# STM32H563 register map
STM32H563xx Cortex-M33 mini SVD fixture for testing
CPU: CM33
Registers are 32-bit, read-write, reset 0x0 unless marked. A register's access mark holds for its fields unless they carry their own. Offsets are from the block's base; lines under a group give offsets from that group; [hi:lo] are bit positions; {n}, {i} and the like mark numbered series; 'fields as' and 'values as' point back to an identical list; <NAME> marks a mode.

## Memory map
0x40013800 USART1 — Universal synchronous/asynchronous receiver transmitter
0x40020000 GPDMA1 — General purpose direct memory access controller
0x42020000 GPIOA — General-purpose I/Os
0x42020400 GPIOB
0x44020C00 RCC — Reset and clock control

## Interrupts
61 USART1 — USART1 global interrupt

## GPIOA — General-purpose I/Os
Base 0x42020000
Same registers: GPIOB 0x42020400
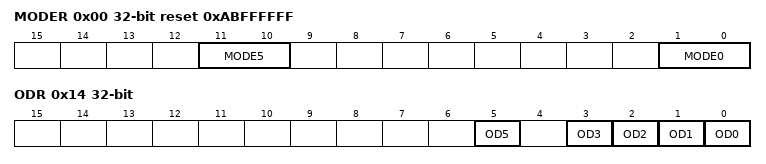
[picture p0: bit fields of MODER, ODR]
0x00 MODER reset 0xABFFFFFF — GPIO port mode register
  [11:10] MODE5 — Port x configuration I/O pin 5
    0=Input mode; 1=Output (General purpose output mode); 2=Alternate function mode; 3=Analog mode (reset state)
  [1:0] MODE0 — Port x configuration I/O pin 0
    values as MODE5
0x14 ODR — GPIO port output data register
  [5] OD5 — Port output data pin 5
  [n] OD{n} (n=0..3) — Port output data pin
0x20 AFR{x} (x=L,H; step 0x4) access not given — GPIO alternate function register
  [3:0] AFSEL0 — Alternate function selection

## RCC — Reset and clock control
Base 0x44020C00
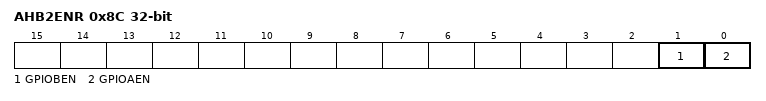
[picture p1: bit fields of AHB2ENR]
0x8C AHB2ENR — RCC AHB2 peripheral clock register
  [1] GPIOBEN — GPIOB clock enable
  [0] GPIOAEN — GPIOA clock enable
0xA4 APB2ENR — RCC APB2 peripheral clock register
  [14] USART1EN — USART1 clock enable

## USART1 — Universal synchronous/asynchronous receiver transmitter
Base 0x40013800
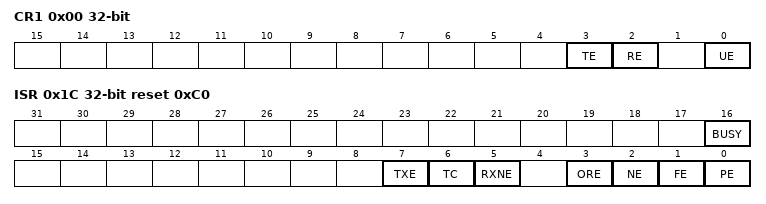
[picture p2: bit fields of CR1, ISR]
0x00 CR1 access not given — Control register 1
  [3] TE — Transmitter enable
  [2] RE — Receiver enable
  [0] UE — USART enable
0x1C ISR ro reset 0xC0 — Interrupt and status register
  [16] BUSY — Busy flag
  [7] TXE — Transmit data register empty
  [6] TC — Transmission complete
  [5] RXNE — Read data register not empty
  [3] ORE — Overrun error
  [2] NE — Noise detection flag
  [1] FE — Framing error
  [0] PE — Parity error

## GPDMA1 — General purpose direct memory access controller
Base 0x40020000
{0x50+0x50*i} C{i} (i=0..1) group
  0x14 CR access not given — Channel control register
    [0] EN — Channel enable
